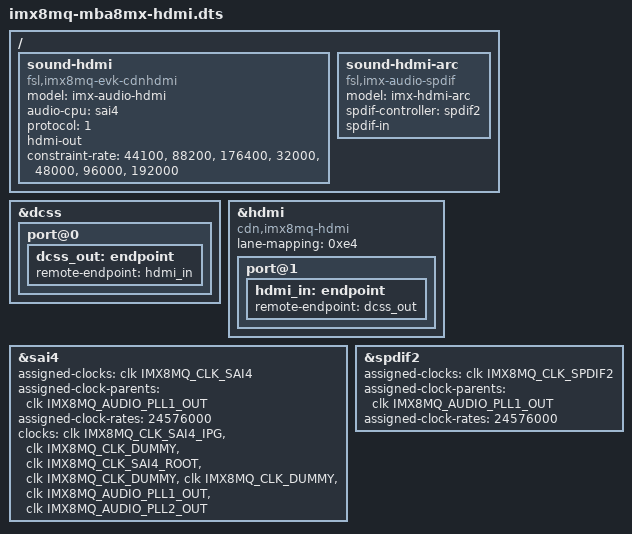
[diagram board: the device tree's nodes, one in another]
// SPDX-License-Identifier: (GPL-2.0-or-later OR MIT)
/*
 * Copyright 2019-2021 TQ-Systems GmbH
 */

#include "imx8mq-mba8mx.dts"


/ {
	sound-hdmi {
		compatible = "fsl,imx8mq-evk-cdnhdmi",
				"fsl,imx-audio-cdnhdmi";
		model = "imx-audio-hdmi";
		audio-cpu = <&sai4>;
		protocol = <1>;
		hdmi-out;
		constraint-rate = <44100>,
				<88200>,
				<176400>,
				<32000>,
				<48000>,
				<96000>,
				<192000>;
	};

	sound-hdmi-arc {
		compatible = "fsl,imx-audio-spdif";
		model = "imx-hdmi-arc";
		spdif-controller = <&spdif2>;
		spdif-in;
	};
};

&dcss {
	status = "okay";

	port@0 {
		dcss_out: endpoint {
			  remote-endpoint = <&hdmi_in>;
		};
	};
};

&hdmi {
	compatible = "cdn,imx8mq-hdmi";
	lane-mapping = <0xe4>;
	status = "okay";

	port@1 {
		hdmi_in: endpoint {
			remote-endpoint = <&dcss_out>;
		};
	};
};

&sai4 {
	assigned-clocks = <&clk IMX8MQ_CLK_SAI4>;
	assigned-clock-parents = <&clk IMX8MQ_AUDIO_PLL1_OUT>;
	assigned-clock-rates = <24576000>;
	clocks = <&clk IMX8MQ_CLK_SAI4_IPG>, <&clk IMX8MQ_CLK_DUMMY>,
		<&clk IMX8MQ_CLK_SAI4_ROOT>, <&clk IMX8MQ_CLK_DUMMY>,
		<&clk IMX8MQ_CLK_DUMMY>, <&clk IMX8MQ_AUDIO_PLL1_OUT>,
		<&clk IMX8MQ_AUDIO_PLL2_OUT>;
	clock-names = "bus", "mclk0", "mclk1", "mclk2", "mclk3", "pll8k", "pll11k";
	status = "okay";
};

&spdif2 {
	assigned-clocks = <&clk IMX8MQ_CLK_SPDIF2>;
	assigned-clock-parents = <&clk IMX8MQ_AUDIO_PLL1_OUT>;
	assigned-clock-rates = <24576000>;
	status = "okay";
};

